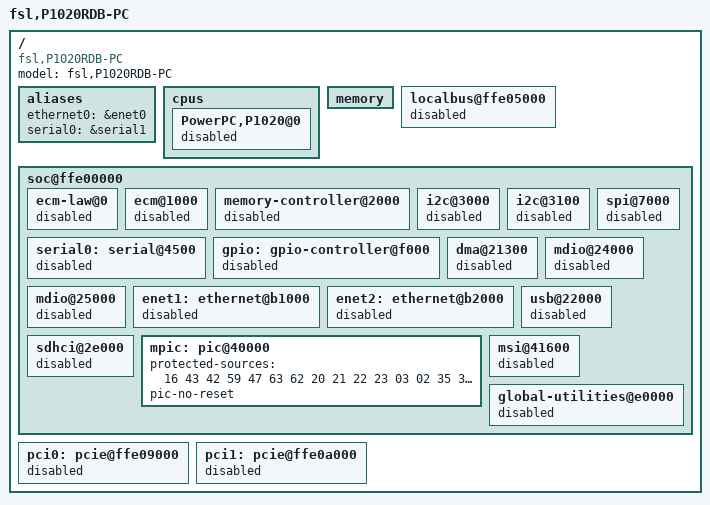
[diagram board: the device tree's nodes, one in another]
/include/ "p1020rdb-pc_32b.dts"
/ {
	model = "fsl,P1020RDB-PC";
	compatible = "fsl,P1020RDB-PC";
	aliases {
		ethernet0 = &enet0;
		serial0 = &serial1;
		};
	cpus {
		PowerPC,P1020@0 {
			status = "disabled";
		};
	};
	memory {
		device_type = "memory";
	};
	localbus@ffe05000 {
		status = "disabled";
	};
	soc@ffe00000 {
		ecm-law@0 {
			status = "disabled";
		};
		ecm@1000 {
			status = "disabled";
		};
		memory-controller@2000 {
			status = "disabled";
		};
		i2c@3000 {
			status = "disabled";
		};
		i2c@3100 {
			status = "disabled";
		};
		serial0: serial@4500 {
			status = "disabled";
		};
		spi@7000 {
			status = "disabled";
		};
		gpio: gpio-controller@f000 {
			status = "disabled";
		};
		dma@21300 {
			status = "disabled";
		};
		mdio@24000 {
			status = "disabled";
		};
		mdio@25000 {
			status = "disabled";
		};
		enet1: ethernet@b1000 {
			status = "disabled";
		};
		enet2: ethernet@b2000 {
			status = "disabled";
		};
		usb@22000 {
			status = "disabled";
		};
		sdhci@2e000 {
			status = "disabled";
		};
		mpic: pic@40000 {
			protected-sources = <
			16 		 
			43 42 59	 
			47 63 62 	 
			20 21 22 23	 
			03 02 		 
			35 36 40	 
			51 52 67	 
			31 32 33	 
			25 26 27	 
			28 72 58 	 
			0xb0 0xb1 0xb2	 
			0xb3 0xb4 0xb5
			0xb6 0xb7
			0xe0 0xe1 0xe2	 
			0xe3 0xe4 0xe5
			0xe6 0xe7		 
			>;
			pic-no-reset;
		};
		msi@41600 {
			status = "disabled";
		};
		global-utilities@e0000 {	 
			status = "disabled";
		};
	};
	pci0: pcie@ffe09000 {
		status = "disabled";
	};
	pci1: pcie@ffe0a000 {
		status = "disabled";
	};
};
